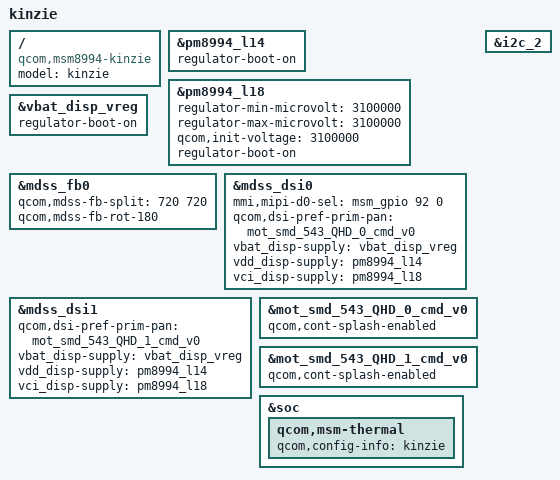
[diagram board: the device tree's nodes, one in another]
/* Copyright (c) 2015, Motorla Mobility LLC. All rights reserved.
 *
 * This program is free software; you can redistribute it and/or modify
 * it under the terms of the GNU General Public License version 2 and
 * only version 2 as published by the Free Software Foundation.
 *
 * This program is distributed in the hope that it will be useful,
 * but WITHOUT ANY WARRANTY; without even the implied warranty of
 * MERCHANTABILITY or FITNESS FOR A PARTICULAR PURPOSE.  See the
 * GNU General Public License for more details.
 */

#include "dsi-panel-mot-smd-543-QHD-cmd.dtsi"

/ {
	model = "kinzie";
	compatible = "qcom,msm8994-kinzie", "qcom,msm8994-moto", "qcom,msm8994";
};

&pm8994_l14 {
	regulator-boot-on;
};

&pm8994_l18 {
	regulator-min-microvolt = <3100000>;
	regulator-max-microvolt = <3100000>;
	qcom,init-voltage = <3100000>;
	regulator-boot-on;
};

&vbat_disp_vreg {
	regulator-boot-on;
};

&mdss_fb0 {
	qcom,mdss-fb-split = <720 720>;
	qcom,mdss-fb-rot-180;
};

&mdss_dsi0 {
	mmi,mipi-d0-sel = <&msm_gpio 92 0>;
	qcom,dsi-pref-prim-pan = <&mot_smd_543_QHD_0_cmd_v0>;
	vbat_disp-supply = <&vbat_disp_vreg>;
	vdd_disp-supply = <&pm8994_l14>;
	vci_disp-supply = <&pm8994_l18>;

	#include "dsi-panel-mot-smd-543-QHD-cmd-supplies.dtsi"
};

&mdss_dsi1 {
	qcom,dsi-pref-prim-pan = <&mot_smd_543_QHD_1_cmd_v0>;
	vbat_disp-supply = <&vbat_disp_vreg>;
	vdd_disp-supply = <&pm8994_l14>;
	vci_disp-supply = <&pm8994_l18>;

	#include "dsi-panel-mot-smd-543-QHD-cmd-supplies.dtsi"
};

&mot_smd_543_QHD_0_cmd_v0 {
	qcom,cont-splash-enabled;
};

&mot_smd_543_QHD_1_cmd_v0 {
	qcom,cont-splash-enabled;
};

&i2c_2 {
	/delete-node/ atmel_mxt_ts@4a;
};

&soc {
	qcom,msm-thermal {
		qcom,config-info = "kinzie";
	};
};
